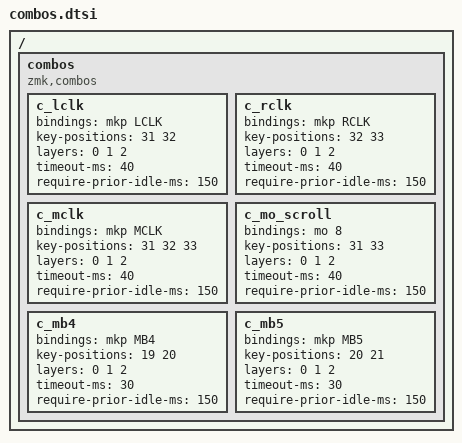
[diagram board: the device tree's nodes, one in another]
/ {
    combos {
        compatible = "zmk,combos";

        c_lclk {
            bindings = <&mkp LCLK>;
            key-positions = <31 32>;
            layers = <0 1 2>;
            timeout-ms = <40>;
            require-prior-idle-ms = <150>;
        };

        c_rclk {
            bindings = <&mkp RCLK>;
            key-positions = <32 33>;
            layers = <0 1 2>;
            timeout-ms = <40>;
            require-prior-idle-ms = <150>;
        };

        c_mclk {
            bindings = <&mkp MCLK>;
            key-positions = <31 32 33>;
            layers = <0 1 2>;
            timeout-ms = <40>;
            require-prior-idle-ms = <150>;
        };

        c_mo_scroll {
            bindings = <&mo 8>;
            key-positions = <31 33>;
            layers = <0 1 2>;
            timeout-ms = <40>;
            require-prior-idle-ms = <150>;
        };

        c_mb4 {
            bindings = <&mkp MB4>;
            key-positions = <19 20>;
            layers = <0 1 2>;
            timeout-ms = <30>;
            require-prior-idle-ms = <150>;
        };

        c_mb5 {
            bindings = <&mkp MB5>;
            key-positions = <20 21>;
            layers = <0 1 2>;
            timeout-ms = <30>;
            require-prior-idle-ms = <150>;
        };
    };
};
